VERSION ""

NS_ :

BS_:

BU_: ECU
VAL_TABLE_ NoAxisEvent 5 "NoAxisEvent" ;
VAL_TABLE_ EventIfActive 4 "EventIfActive" ;
VAL_TABLE_ Event 3 "Event" ;
VAL_TABLE_ CyclicIfActive 2 "CyclicIfActive" ;
VAL_TABLE_ Cyclic 1 "Cyclic" ;
VAL_TABLE_ NoMsgSendType 0 "Description for the value '0x0'" ;

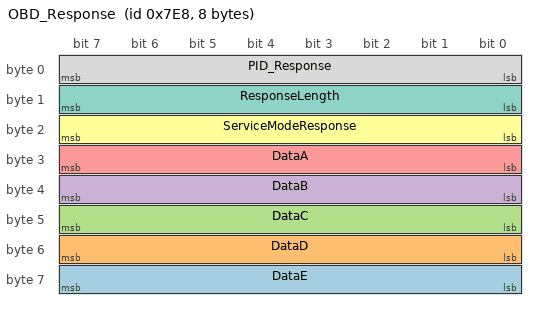
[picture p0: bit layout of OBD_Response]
BO_ 2024 OBD_Response: 8 ECU
 SG_ DataE : 56|8@1+ (1,0) [0|0] "" Vector__XXX
 SG_ DataD : 48|8@1+ (1,0) [0|0] "" Vector__XXX
 SG_ DataC : 40|8@1+ (1,0) [0|0] "" Vector__XXX
 SG_ DataB : 32|8@1+ (1,0) [0|0] "" Vector__XXX
 SG_ DataA : 24|8@1+ (1,0) [0|0] "" Vector__XXX
 SG_ ServiceModeResponse : 16|8@1+ (1,0) [0|0] "" Vector__XXX
 SG_ ResponseLength : 8|8@1+ (1,0) [0|0] "" Vector__XXX
 SG_ PID_Response : 0|8@1+ (1,0) [0|0] "" Vector__XXX

BO_ 2015 OBD_Request: 8 Vector__XXX
 SG_ ServiceMode : 8|8@1+ (1,0) [0|255] "" Vector__XXX
 SG_ PID : 0|8@1+ (1,0) [0|255] "" Vector__XXX

BA_DEF_  "BusType" STRING ;
BA_DEF_DEF_  "BusType" "CAN";
